# STM32H563 register map
File version: 1.6
CPU: CM33 r0p0, little endian, MPU, FPU, 4 interrupt priority bits
Registers are 32-bit, read-write, reset 0x0 unless marked. A register's access mark holds for its fields unless they carry their own. Offsets are from the block's base; [hi:lo] are bit positions; {n}, {i} and the like mark numbered series; 'fields as' and 'values as' point back to an identical list.

## GPDMA1 — General purpose direct memory access controller
Base 0x40020000
Same registers: GPDMA2 0x40021000, SEC_GPDMA1 0x50020000, SEC_GPDMA2 0x50021000
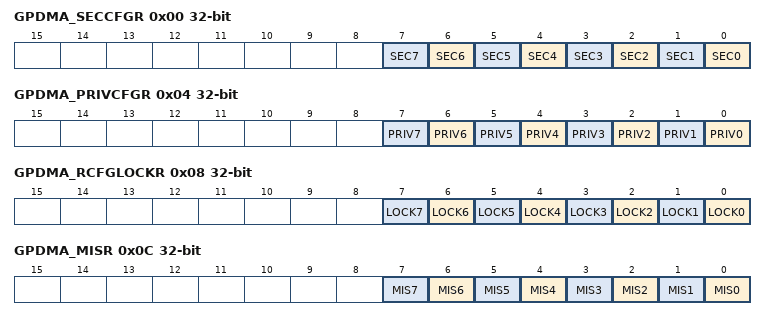
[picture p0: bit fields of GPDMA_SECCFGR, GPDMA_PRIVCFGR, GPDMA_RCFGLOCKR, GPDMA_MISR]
0x00 GPDMA_SECCFGR — GPDMA secure configuration register
  [all] fields
    0=non-secure; 1=secure
  [n] SEC{n} (n=0..7) — secure state of channel x (x = 7 to 0)
0x04 GPDMA_PRIVCFGR — GPDMA privileged configuration register
  [all] fields
    0=unprivileged; 1=privileged
  [n] PRIV{n} (n=0..7) — privileged state of channel x (x = 7 to 0)
0x08 GPDMA_RCFGLOCKR — GPDMA configuration lock register
  [all] fields
    0=secure privilege configuration of the channel x is writable; 1=secure privilege configuration of the channel x is not writable
  [n] LOCK{n} (n=0..7) — lock the configuration of GPDMA_SECCFGR.SECx and GPDMA_PRIVCFGR.PRIVx, until a global GPDMA reset (x = 7 to 0) This bit is cleared after reset and, once set, it cannot be reset until a global GPDMA reset.
0x0C GPDMA_MISR ro — GPDMA non-secure masked interrupt status register
  [all] fields
    0=no interrupt occurred on channel x; 1=an interrupt occurred on channel x
  [n] MIS{n} (n=0..7) — masked interrupt status of channel x (x = 7 to 0)
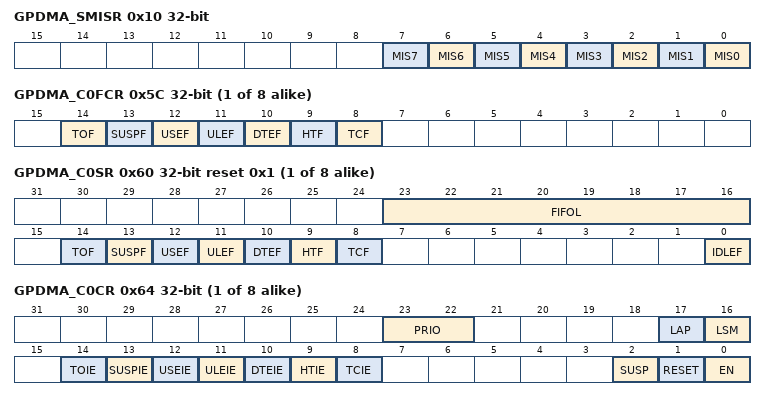
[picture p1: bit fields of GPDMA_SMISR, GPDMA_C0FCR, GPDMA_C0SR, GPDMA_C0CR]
0x10 GPDMA_SMISR ro — GPDMA secure masked interrupt status register
  [all] fields
    0=no interrupt occurred on the secure channel x; 1=an interrupt occurred on the secure channel x
  [n] MIS{n} (n=0..7) — masked interrupt status of the secure channel x (x = 7 to 0)
{0x50+0x80*i} GPDMA_C{i}LBAR (i=0..7) — GPDMA channel {i} linked-list base address register
  [31:16] LBA — linked-list base address of GPDMA channel x
{0x5C+0x80*i} GPDMA_C{i}FCR wo (i=0..7) — GPDMA channel {i} flag clear register
  [14] TOF — trigger overrun flag clear
    0=no effect; 1=corresponding TOF flag cleared
  [13] SUSPF — completed suspension flag clear
    0=no effect; 1=corresponding SUSPF flag cleared
  [12] USEF — user setting error flag clear
    0=no effect; 1=corresponding USEF flag cleared
  [11] ULEF — update link transfer error flag clear
    0=no effect; 1=corresponding ULEF flag cleared
  [10] DTEF — data transfer error flag clear
    0=no effect; 1=corresponding DTEF flag cleared
  [9] HTF — half transfer flag clear
    0=no effect; 1=corresponding HTF flag cleared
  [8] TCF — transfer complete flag clear
    0=no effect; 1=corresponding TCF flag cleared
{0x60+0x80*i} GPDMA_C{i}SR ro reset 0x1 (i=0..7) — GPDMA channel {i} status register
  [23:16] FIFOL — monitored FIFO level Number of available write beats in the FIFO, in units of the programmed destination data width (see GPDMA_CxTR1.DDW_LOG2[1:0], in units of bytes, half-words, or words). Note: After having suspended an active transfer, the user may need to read FIFOL[7:0], additionally to GPDMA_CxBR1.BDNT[15:0] and GPDMA_CxBR1.BRC[10:0], to know how many data have been transferred to the destination. Before reading, the user may wait for the transfer to be suspended (GPDMA_CxSR.SUSPF = 1).
  [14] TOF — trigger overrun flag
    0=no trigger overrun event; 1=a trigger overrun event occurred
  [13] SUSPF — completed suspension flag
    0=no completed suspension event; 1=a completed suspension event occurred
  [12] USEF — user setting error flag
    0=no user setting error event; 1=a user setting error event occurred
  [11] ULEF — update link transfer error flag
    0=no update link transfer error event; 1=a master bus error event occurred while updating a linked-list register from memory
  [10] DTEF — data transfer error flag
    0=no data transfer error event; 1=a master bus error event occurred on a data transfer
  [9] HTF — half transfer flag A half transfer event is either a half block transfer or a half 2D/repeated block transfer, depending on the transfer complete event mode (GPDMA_CxTR2.TCEM[1:0]). A half block transfer occurs when half of the bytes of the source block size (rounded up integer of GPDMA_CxBR1.BNDT[15:0]/2) has been transferred to the destination. A half 2D/repeated block transfer occurs when half of the repeated blocks (rounded up integer of (GPDMA_CxBR1.BRC[10:0]+1)/2)) has been transferred to the destination.
    0=no half transfer event; 1=a half transfer event occurred
  [8] TCF — transfer complete flag A transfer complete event is either a block transfer complete, a 2D/repeated block transfer complete, a LLI transfer complete including the upload of the next LLI if any, or the full linked-list completion, depending on the transfer complete event mode (GPDMA_CxTR2.TCEM[1:0]).
    0=no transfer complete event; 1=a transfer complete event occurred
  [0] IDLEF — idle flag This idle flag is de-asserted by hardware when the channel is enabled (GPDMA_CxCR.EN = 1) with a valid channel configuration (no USEF to be immediately reported). This idle flag is asserted after hard reset or by hardware when the channel is back in idle state (in suspended or disabled state).
    0=channel not in idle state; 1=channel in idle state
{0x64+0x80*i} GPDMA_C{i}CR access per field (i=0..7) — GPDMA channel {i} control register
  [23:22] PRIO rw — priority level of the channel x GPDMA transfer versus others Note: This bit must be written when EN = 0. This bit is read-only when EN = 1.
    0=low priority, low weight; 1=low priority, mid weight; 2=low priority, high weight; 3=high priority
  [17] LAP rw — linked-list allocated port This bit is used to allocate the master port for the update of the GPDMA linked-list registers from the memory. Note: This bit must be written when EN=0. This bit is read-only when EN=1.
    0=port 0 (AHB) allocated; 1=port 1 (AHB) allocated
  [16] LSM rw — Link step mode First the (possible 1D/repeated) block transfer is executed as defined by the current internal register file until GPDMA_CxBR1.BNDT[15:0] = 0 and GPDMA_CxBR1.BRC[10:0] = 0 if present. Secondly the next linked-list data structure is conditionally uploaded from memory as defined by GPDMA_CxLLR. Then channel execution is completed. Note: This bit must be written when EN=0. This bit is read-only when EN=1.
    0=channel executed for the full linked-list and completed at the end of the last LLI (GPDMA_CxLLR = 0). The 16 low-significant bits of the link address are null (LA[15:0] = 0) and all the update bits are null (UT1 =UB1 = UT2 = USA = UDA = ULL = 0 and UT3 = UB2 = 0 if present). Then GPDMA_CxBR1.BNDT[15:0] = 0 and GPDMA_CxBR1.BRC[10:0] = 0 if present.; 1=channel executed once for the current LLI
  [14] TOIE rw — trigger overrun interrupt enable
    0=interrupt disabled; 1=interrupt enabled
  [13] SUSPIE rw — completed suspension interrupt enable
    0=interrupt disabled; 1=interrupt enabled
  [12] USEIE rw — user setting error interrupt enable
    0=interrupt disabled; 1=interrupt enabled
  [11] ULEIE rw — update link transfer error interrupt enable
    0=interrupt disabled; 1=interrupt enabled
  [10] DTEIE rw — data transfer error interrupt enable
    0=interrupt disabled; 1=interrupt enabled
  [9] HTIE rw — half transfer complete interrupt enable
    0=interrupt disabled; 1=interrupt enabled
  [8] TCIE rw — transfer complete interrupt enable
    0=interrupt disabled; 1=interrupt enabled
  [2] SUSP rw — suspend Writing 1 into the field RESET (bit 1) causes the hardware to de-assert this bit, whatever is written into this bit 2. Else: Software must write 1 in order to suspend an active channel i.e. a channel with an ongoing GPDMA transfer over its master ports. The software must write 0 in order to resume a suspended channel, following the programming sequence detailed in .
    0=write: resume channel, read: channel not suspended; 1=write: suspend channel, read: channel suspended
  [1] RESET wo — reset This bit is write only. Writing 0 has no impact. Writing 1 implies the reset of the following: the FIFO, the channel internal state, SUSP and EN bits (whatever is written receptively in bit 2 and bit 0). The reset is effective when the channel is in steady state, meaning one of the following: - active channel in suspended state (GPDMA_CxSR.SUSPF = 1 and GPDMA_CxSR.IDLEF = GPDMA_CxCR.EN = 1) - channel in disabled state (GPDMA_CxSR.IDLEF = 1 and GPDMA_CxCR.EN = 0). After writing a RESET, to continue using this channel, the user must explicitly reconfigure the channel including the hardware-modified configuration registers (GPDMA_CxBR1, GPDMA_CxSAR and GPDMA_CxDAR) before enabling again the channel (see the programming sequence in ).
    0=no channel reset; 1=channel reset
  [0] EN rw — enable Writing 1 into the field RESET (bit 1) causes the hardware to de-assert this bit, whatever is written into this bit 0. Else: this bit is de-asserted by hardware when there is a transfer error (master bus error or user setting error) or when there is a channel transfer complete (channel ready to be configured, e.g. if LSM=1 at the end of a single execution of the LLI). Else, this bit can be asserted by software. Writing 0 into this EN bit is ignored.
    0=write: ignored, read: channel disabled; 1=write: enable channel, read: channel enabled
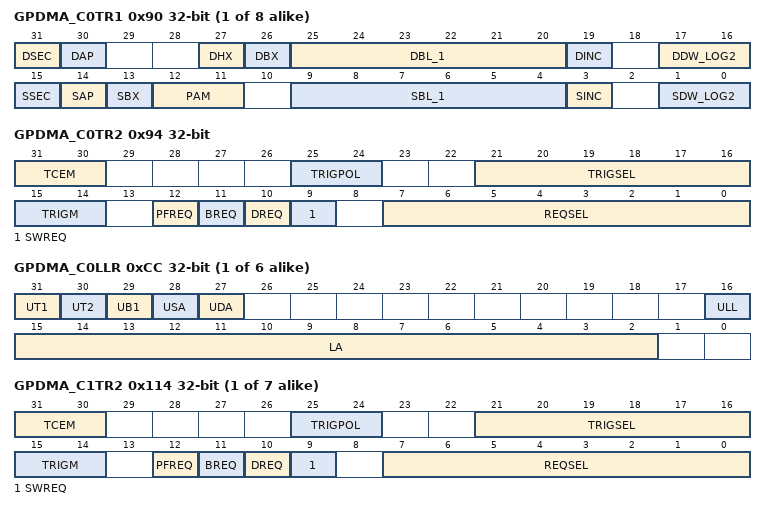
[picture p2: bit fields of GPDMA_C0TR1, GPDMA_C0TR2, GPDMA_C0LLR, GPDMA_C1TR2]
{0x90+0x80*i} GPDMA_C{i}TR1 (i=0..7) — GPDMA channel {i} transfer register 1
  [31] DSEC — security attribute of the GPDMA transfer to the destination If GPDMA_SECCFGR.SECx = 1 and the access is secure: This is a secure register bit. This bit can only be read by a secure software. This bit must be written by a secure software when GPDMA_SECCFGR.SECx = 1. A secure write is ignored when GPDMA_SECCFGR.SECx = 0. When GPDMA_SECCFGR.SECx is de-asserted, this DSEC bit is also de-asserted by hardware (on a secure reconfiguration of the channel as non-secure), and the GPDMA transfer to the destination is non-secure.
    0=GPDMA transfer non-secure; 1=GPDMA transfer secure
  [30] DAP — destination allocated port This bit is used to allocate the master port for the destination transfer Note: This bit must be written when EN = 0. This bit is read-only when EN = 1.
    0=port 0 (AHB) allocated; 1=port 1 (AHB) allocated
  [27] DHX — destination half-word exchange If the destination data size is shorter than a word, this bit is ignored. If the destination data size is a word:
    0=no halfword-based exchanged within word; 1=the two consecutive (post PAM) half-words are exchanged in each destination word
  [26] DBX — destination byte exchange If the destination data size is a byte, this bit is ignored. If the destination data size is not a byte:
    0=no byte-based exchange within half-word; 1=the two consecutive (post PAM) bytes are exchanged in each destination half-word
  [25:20] DBL_1 — destination burst length minus 1, between 0 and 63 The burst length unit is one data named beat within a burst. If DBL_1[5:0] =0 , the burst can be named as single. Each data/beat has a width defined by the destination data width DDW_LOG2[1:0]. Note: If a burst transfer crossed a 1-Kbyte address boundary on a AHB transfer, the GPDMA modifies and shortens the programmed burst into singles or bursts of lower length, to be compliant with the AHB protocol. If a burst transfer is of length greater than the FIFO size of the channel x, the GPDMA modifies and shortens the programmed burst into singles or bursts of lower length, to be compliant with the FIFO size. Transfer performance is lower, with GPDMA re-arbitration between effective and lower singles/bursts, but the data integrity is guaranteed.
  [19] DINC — destination incrementing burst The destination address, pointed by GPDMA_CxDAR, is kept constant after a burst beat/single transfer, or is incremented by the offset value corresponding to a contiguous data after a burst beat/single transfer.
    0=fixed burst; 1=contiguously incremented burst
  [17:16] DDW_LOG2 — binary logarithm of the destination data width of a burst, in bytes Note: Setting a 8-byte data width causes a user setting error to be reported and none transfer is issued. A destination burst transfer must have an aligned address with its data width (start address GPDMA_CxDAR[2:0] and address offset GPDMA_CxTR3.DAO[2:0], versus DDW_LOG2[1:0]). Otherwise a user setting error is reported and no transfer is issued.
    0=byte; 1=half-word (2 bytes); 2=word (4 bytes); 3=user setting error reported and no transfer issued
  [15] SSEC — security attribute of the GPDMA transfer from the source If GPDMA_SECCFGR.SECx = 1 and the access is secure: This is a secure register bit. This bit can only be read by a secure software. This bit must be written by a secure software when GPDMA_SECCFGR.SECx =1 . A secure write is ignored when GPDMA_SECCFGR.SECx = 0. When GPDMA_SECCFGR.SECx is de-asserted, this SSEC bit is also de-asserted by hardware (on a secure reconfiguration of the channel as non-secure), and the GPDMA transfer from the source is non-secure.
    0=GPDMA transfer non-secure; 1=GPDMA transfer secure
  [14] SAP — source allocated port This bit is used to allocate the master port for the source transfer Note: This bit must be written when EN = 0. This bit is read-only when EN = 1.
    0=port 0 (AHB) allocated; 1=port 1 (AHB) allocated
  [13] SBX — source byte exchange within the unaligned half-word of each source word If the source data width is shorter than a word, this bit is ignored. If the source data width is a word:
    0=no byte-based exchange within the unaligned half-word of each source word; 1=the two consecutive bytes within the unaligned half-word of each source word are exchanged
  [12:11] PAM — padding/alignment mode If DDW_LOG2[1:0] = SDW_LOG2[1:0]: if the data width of a burst destination transfer is equal to the data width of a burst source transfer, these bits are ignored. Else, in the following enumerated values, the condition PAM_1 is when destination data width is higher that source data width, and the condition PAM_2 is when destination data width is higher than source data width. 1x: successive source data are FIFO queued and packed at the destination data width, in a left (LSB) to right (MSB) order (named little endian), before a destination transfer 1x: source data is FIFO queued and unpacked at the destination data width, to be transferred in a left (LSB) to right (MSB) order (named little endian) to the destination Note: If the transfer from the source peripheral is configured with peripheral flow-control mode (SWREQ = 0 and PFREQ = 1 and DREQ = 0), and if the destination data width the source data width, packing is not supported.
    0=B_0x0_PAM_1 (source data is transferred as right aligned, padded with 0s up to the destination data width); 1=B_0x1_PAM_1 (source data is transferred as right aligned, sign extended up to the destination data width)
  [9:4] SBL_1 — source burst length minus 1, between 0 and 63 The burst length unit is one data named beat within a burst. If SBL_1[5:0] =0 , the burst can be named as single. Each data/beat has a width defined by the destination data width SDW_LOG2[1:0]. Note: If a burst transfer crossed a 1-Kbyte address boundary on a AHB transfer, the GPDMA modifies and shortens the programmed burst into singles or bursts of lower length, to be compliant with the AHB protocol. If a burst transfer is of length greater than the FIFO size of the channel x, the GPDMA modifies and shortens the programmed burst into singles or bursts of lower length, to be compliant with the FIFO size. Transfer performance is lower, with GPDMA re-arbitration between effective and lower singles/bursts, but the data integrity is guaranteed.
  [3] SINC — source incrementing burst The source address, pointed by GPDMA_CxSAR, is kept constant after a burst beat/single transfer or is incremented by the offset value corresponding to a contiguous data after a burst beat/single transfer.
    0=fixed burst; 1=contiguously incremented burst
  [1:0] SDW_LOG2 — binary logarithm of the source data width of a burst in bytes Note: Setting a 8-byte data width causes a user setting error to be reported and no transfer is issued. A source block size must be a multiple of the source data width (GPDMA_CxBR1.BNDT[2:0] versus SDW_LOG2[1:0]). Otherwise, a user setting error is reported and no transfer is issued. A source burst transfer must have an aligned address with its data width (start address GPDMA_CxSAR[2:0] versus SDW_LOG2[1:0]). Otherwise, a user setting error is reported and none transfer is issued.
    values as DDW_LOG2
0x94 GPDMA_C0TR2 — GPDMA channel 0 transfer register 2
  [31:30] TCEM — transfer complete event mode These bits define the transfer granularity for the transfer complete and half transfer complete events generation. Note: If the initial LLI0 data transfer is null/void (directly programmed by the internal register file with GPDMA_CxBR1.BNDT[15:0] = 0), then neither the complete transfer event nor the half transfer event is generated. Note: If the initial LLI0 data transfer is null/void (directly programmed by the internal register file with GPDMA_CxBR1.BNDT[15:0] = 0), then neither the complete transfer event nor the half transfer event is generated. Note: If the initial LLI0 data transfer is null/void (i.e. directly programmed by the internal register file with GPDMA_CxBR1.BNDT[15:0] =0 ), then the half transfer event is not generated, and the transfer complete event is generated when is completed the loading of the LLI1.
    0=at block level (when GPDMA_CxBR1.BNDT[15:0] = 0): the complete (and the half) transfer event is generated at the (respectively half of the) end of a block; 1=channel x = 0 to 11, same as 00; channel x=12 to 15, at 2D/repeated block level (when GPDMA_CxBR1.BRC[10:0] = 0 and GPDMA_CxBR1.BNDT[15:0] = 0), the complete (and the half) transfer event is generated at the end (respectively half of the end) of the 2D/repeated block; 2=at LLI level: the complete transfer event is generated at the end of the LLI transfer, including the update of the LLI if any. The half transfer event is generated at the half of the LLI data transfer (the LLI data transfer being a block transfer or a 2D/repeated block transfer for channel x = 12 to 15), if any data transfer.; 3=at channel level: the complete transfer event is generated at the end of the last LLI transfer. The half transfer event is generated at the half of the data transfer of the last LLI. The last LLI updates the link address GPDMA_CxLLR.LA[15:2] to zero and clears all the GPDMA_CxLLR update bits (UT1, UT2, UB1, USA, UDA and ULL, plus UT3 and UB2 if present). If the channel transfer is continuous/infinite, no event is generated.
  [25:24] TRIGPOL — trigger event polarity These bits define the polarity of the selected trigger event input defined by TRIGSEL[5:0].
    0=no trigger (masked trigger event); 1=trigger on the rising edge; 2=trigger on the falling edge; 3=same as 00
  [21:16] TRIGSEL — trigger event input selection These bits select the trigger event input of the GPDMA transfer (as per ), with an active trigger event if TRIGPOL[1:0] different 00.
  [15:14] TRIGM — trigger mode These bits define the transfer granularity for its conditioning by the trigger..
    0=at block level: the first burst read of each block transfer is conditioned by one hit trigger (channel x = 12 to 15, for each block if a 2D/repeated block is configured with GPDMA_CxBR1.BRC[10:0] different 0); 1=channel x = 0 to 11, same as 00; channel x=12 to 15, at 2D/repeated block level, the; 2=at link level: a LLI link transfer is conditioned by one hit trigger. The LLI data transfer (if any) is not conditioned.; 3=at programmed burst level: If SWREQ = 1, each programmed burst read is conditioned by one hit trigger. If SWREQ = 0, each programmed burst that is requested by the selected peripheral, is conditioned by one hit trigger.
  [12] PFREQ — Hardware request in peripheral flow control mode Important: If a given channel x is not implemented with this feature, this bit is reserved and PFREQ is not present (see for the list of the implemented channels with this feature. If the channel x is activated (GPDMA_CxCR.EN asserted) with SWREQ = 1 (software request for a memory-to-memory transfer), this bit is ignored. Else: Note: In peripheral flow control mode, there are the following restrictions: - no 2D/repeated block support (GPDMA_CxBR1.BRC[10:0] must be set to 0 if present) - the peripheral must be set as the source of the transfer (DREQ = 0). - data packing to a wider destination width is not supported (if destination width source data width, GPDMA_CxTR1.PAM[1] must be set to 0). - GPDMA_CxBR1.BNDT[15:0] must be programmed as a multiple of the source (peripheral) burst size.
    0=the selected hardware request is driven by a peripheral with a hardware request/acknowledge protocol in GPDMA control mode. The GPDMA is programmed with GPDMA_CxCTR1.BNDT[15:0] and this is internally used by the hardware for the block transfer completion.; 1=the selected hardware request is driven by a peripheral with a hardware request/acknowledge protocol in peripheral control mode. The GPDMA block transfer can be early completed by the peripheral itself (see for more details).
  [11] BREQ — Block hardware request If the channel x is activated (GPDMA_CxCR.EN asserted) with SWREQ = 1 (software request for a memory-to-memory transfer), this bit is ignored. Else:
    0=the selected hardware request is driven by a peripheral with a hardware request/acknowledge protocol at a burst level; 1=the selected hardware request is driven by a peripheral with a hardware request/acknowledge protocol at a block level (see )
  [10] DREQ — destination hardware request This bit is ignored if channel x is activated (GPDMA_CxCR.EN asserted) with SWREQ = 1 (software request for a memory-to-memory transfer). Else: Note: If the channel x is activated (GPDMA_CxCR.EN is asserted) with SWREQ = 0 and PFREQ = 1 (peripheral hardware request with peripheral flow-control mode), any software assertion to this DREQ bit is ignored: in peripheral flow-control mode, only a peripheral-to-memory transfer is supported.
    0=selected hardware request driven by a source peripheral (request signal taken into account by the GPDMA transfer scheduler over the source/read port); 1=selected hardware request driven by a destination peripheral (request signal taken into account by the GPDMA transfer scheduler over the destination/write port)
  [9] SWREQ — software request This bit is internally taken into account when GPDMA_CxCR.EN is asserted.
    0=no software request. The selected hardware request REQSEL[6:0] is taken into account.; 1=software request for a memory-to-memory transfer. The default selected hardware request as per REQSEL[6:0] is ignored.
  [7:0] REQSEL — GPDMA hardware request selection These bits are ignored if channel x is activated (GPDMA_CxCR.EN asserted) with SWREQ = 1 (software request for a memory-to-memory transfer). Else, the selected hardware request is internally taken into account as per . The user must not assign a same input hardware request (same REQSEL[7:0] value) to different active GPDMA channels (GPDMA_CxCR.EN = 1 and GPDMA_CxTR2.SWREQ = 0 for these channels). GPDMA is not intended to hardware support the case of simultaneous enabled channels incorrectly configured with a same hardware peripheral request signal, and there is no user setting error reporting.
{0x98+0x80*i} GPDMA_C{i}BR1 (i=0..5) — GPDMA channel {i} block register 1
  [15:0] BNDT — block number of data bytes to transfer from the source Block size transferred from the source. When the channel is enabled, this field becomes read-only and is decremented, indicating the remaining number of data items in the current source block to be transferred. BNDT[15:0] is programmed in number of bytes, maximum source block size is 64 Kbytes -1. Once the last data transfer is completed (BNDT[15:0] = 0): - if GPDMA_CxLLR.UB1 = 1, this field is updated by the LLI in the memory. - if GPDMA_CxLLR.UB1 = 0 and if there is at least one non null Uxx update bit, this field is internally restored to the programmed value. - if all GPDMA_CxLLR.Uxx = 0 and if GPDMA_CxLLR.LA[15:0] = 0, this field is internally restored to the programmed value (infinite/continuous last LLI). - if GPDMA_CxLLR = 0, this field is kept as zero following the last LLI data transfer. Note: A non-null source block size must be a multiple of the source data width (BNDT[2:0] versus GPDMA_CxTR1.SDW_LOG2[1:0]). Else a user setting error is reported and no transfer is issued. When configured in packing mode (GPDMA_CxTR1.PAM[1] = 1 and destination data width different from source data width), a non-null source block size must be a multiple of the destination data width (BNDT[2:0] versus GPDMA_CxTR1.DDW_LOG2[1:0]). Else a user setting error is reported and no transfer is issued.
{0x9C+0x80*i} GPDMA_C{i}SAR (i=0..7) — GPDMA channel {i} source address register
  [31:0] SA — source address This field is the pointer to the address from which the next data is read. During the channel activity, depending on the source addressing mode (GPDMA_CxTR1.SINC), this field is kept fixed or incremented by the data width (GPDMA_CxTR1.SDW_LOG2[1:0]) after each burst source data, reflecting the next address from which data is read. During the channel activity, this address is updated after each completed source burst, consequently to: the programmed source burst; either in fixed addressing mode or in contiguous-data incremented mode. If contiguously incremented (GPDMA_CxTR1.SINC = 1), then the additional address offset value is the programmed burst size, as defined by GPDMA_CxTR1.SBL_1[5:0] and GPDMA_CxTR1.SDW_LOG2[21:0] the additional source incremented/decremented offset value as programmed by GPDMA_CxBR1.SDEC and GPDMA_CxTR3.SAO[12:0] once/if completed source block transfer, for a channel x with 2D addressing capability (x = 12 to 15). additional block repeat source incremented/decremented offset value as programmed by GPDMA_CxBR1.BRSDEC and GPDMA_CxBR2.BRSAO[15:0] In linked-list mode, after a LLI data transfer is completed, this register is automatically updated by GPDMA from the memory, provided the LLI is set with GPDMA_CxLLR.USA = 1. Note: A source address must be aligned with the programmed data width of a source burst (SA[2:0] versus GPDMA_CxTR1.SDW_LOG2[1:0]). Else, a user setting error is reported and no transfer is issued. When the source block size is not a multiple of the source burst size and is a multiple of the source data width, the last programmed source burst is not completed and is internally shorten to match the block size. In this case, the additional GPDMA_CxTR3.SAO[12:0] is not applied.
{0xA0+0x80*i} GPDMA_C{i}DAR (i=0..7) — GPDMA channel {i} destination address register
  [31:0] DA — destination address This field is the pointer to the address from which the next data is written. During the channel activity, depending on the destination addressing mode (GPDMA_CxTR1.DINC), this field is kept fixed or incremented by the data width (GPDMA_CxTR1.DDW_LOG2[21:0]) after each burst destination data, reflecting the next address from which data is written. During the channel activity, this address is updated after each completed destination burst, consequently to: the programmed destination burst; either in fixed addressing mode or in contiguous-data incremented mode. If contiguously incremented (GPDMA_CxTR1.DINC = 1), then the additional address offset value is the programmed burst size, as defined by GPDMA_CxTR1.DBL_1[5:0] and GPDMA_CxTR1.DDW_LOG2[1:0] the additional destination incremented/decremented offset value as programmed by GPDMA_CxBR1.DDEC and GPDMA_CxTR3.DAO[12:0] once/if completed destination block transfer, for a channel x with 2D addressing capability (x = 12 to 15), the additional block repeat destination incremented/decremented offset value as programmed by GPDMA_CxBR1.BRDDEC and GPDMA_CxBR2.BRDAO[15:0] In linked-list mode, after a LLI data transfer is completed, this register is automatically updated by the GPDMA from the memory, provided the LLI is set with GPDMA_CxLLR.UDA = 1. Note: A destination address must be aligned with the programmed data width of a destination burst (DA[2:0] versus GPDMA_CxTR1.DDW_LOG2[1:0]). Else, a user setting error is reported and no transfer is issued.
{0xCC+0x80*i} GPDMA_C{i}LLR (i=0..5) — GPDMA channel {i} linked-list address register
  [31] UT1 — Update GPDMA_CxTR1 from memory This bit controls the update of GPDMA_CxTR1 from the memory during the link transfer.
    0=no GPDMA_CxTR1 update; 1=GPDMA_CxTR1 update
  [30] UT2 — Update GPDMA_CxTR2 from memory This bit controls the update of GPDMA_CxTR2 from the memory during the link transfer.
    0=no GPDMA_CxTR2 update; 1=GPDMA_CxTR2 update
  [29] UB1 — Update GPDMA_CxBR1 from memory This bit controls the update of GPDMA_CxBR1 from the memory during the link transfer. If UB1 = 0 and if GPDMA_CxLLR different 0, the linked-list is not completed. GPDMA_CxBR1.BNDT[15:0] is then restored to the programmed value after data transfer is completed and before the link transfer.
    0=no GPDMA_CxBR1 update from memory (GPDMA_CxBR1.BNDT[15:0] restored if any link transfer); 1=GPDMA_CxBR1 update
  [28] USA — update GPDMA_CxSAR from memory This bit controls the update of GPDMA_CxSAR from the memory during the link transfer.
    0=no GPDMA_CxSAR update; 1=GPDMA_CxSAR update
  [27] UDA — Update GPDMA_CxDAR register from memory This bit is used to control the update of GPDMA_CxDAR from the memory during the link transfer.
    0=no GPDMA_CxDAR update; 1=GPDMA_CxDAR update
  [16] ULL — Update GPDMA_CxLLR register from memory This bit is used to control the update of GPDMA_CxLLR from the memory during the link transfer.
    0=no GPDMA_CxLLR update; 1=GPDMA_CxLLR update
  [15:2] LA — pointer (16-bit low-significant address) to the next linked-list data structure If UT1 = UT2 = UB1 = USA = UDA = ULL = 0 and if LA[15:20] = 0, the current LLI is the last one. The channel transfer is completed without any update of the linked-list GPDMA register file. Else, this field is the pointer to the memory address offset from which the next linked-list data structure is automatically fetched from, once the data transfer is completed, in order to conditionally update the linked-list GPDMA internal register file (GPDMA_CxCTR1, GPDMA_CxTR2, GPDMA_CxBR1, GPDMA_CxSAR, GPDMA_CxDAR and GPDMA_CxLLR). Note: The user must program the pointer to be 32-bit aligned. The two low-significant bits are write ignored.
{0x94+0x80*i} GPDMA_C{i}TR2 (i=1..7) — GPDMA channel {i} transfer register 2
  [31:30] TCEM — transfer complete event mode These bits define the transfer granularity for the transfer complete and half transfer complete events generation. Note: If the initial LLI0 data transfer is null/void (directly programmed by the internal register file with GPDMA_CxBR1.BNDT[15:0] = 0), then neither the complete transfer event nor the half transfer event is generated. Note: If the initial LLI0 data transfer is null/void (directly programmed by the internal register file with GPDMA_CxBR1.BNDT[15:0] = 0), then neither the complete transfer event nor the half transfer event is generated. Note: If the initial LLI0 data transfer is null/void (i.e. directly programmed by the internal register file with GPDMA_CxBR1.BNDT[15:0] =0 ), then the half transfer event is not generated, and the transfer complete event is generated when is completed the loading of the LLI1.
    values as GPDMA_C0TR2.TCEM
  [25:24] TRIGPOL — trigger event polarity These bits define the polarity of the selected trigger event input defined by TRIGSEL[5:0].
    values as GPDMA_C0TR2.TRIGPOL
  [21:16] TRIGSEL — trigger event input selection These bits select the trigger event input of the GPDMA transfer (as per ), with an active trigger event if TRIGPOL[1:0] different 00.
  [15:14] TRIGM — trigger mode These bits define the transfer granularity for its conditioning by the trigger.
    values as GPDMA_C0TR2.TRIGM
  [12] PFREQ — Hardware request in peripheral flow control mode Important: If a given channel x is not implemented with this feature, this bit is reserved and PFREQ is not present (see for the list of the implemented channels with this feature. If the channel x is activated (GPDMA_CxCR.EN asserted) with SWREQ = 1 (software request for a memory-to-memory transfer), this bit is ignored. Else: Note: In peripheral flow control mode, there are the following restrictions: - no 2D/repeated block support (GPDMA_CxBR1.BRC[10:0] must be set to 0 if present) - the peripheral must be set as the source of the transfer (DREQ = 0). - data packing to a wider destination width is not supported (if destination width source data width, GPDMA_CxTR1.PAM[1] must be set to 0). - GPDMA_CxBR1.BNDT[15:0] must be programmed as a multiple of the source (peripheral) burst size.
    values as GPDMA_C0TR2.PFREQ
  [11] BREQ — Block hardware request If the channel x is activated (GPDMA_CxCR.EN asserted) with SWREQ = 1 (software request for a memory-to-memory transfer), this bit is ignored. Else:
    values as GPDMA_C0TR2.BREQ
  [10] DREQ — destination hardware request This bit is ignored if channel x is activated (GPDMA_CxCR.EN asserted) with SWREQ = 1 (software request for a memory-to-memory transfer). Else: Note: If the channel x is activated (GPDMA_CxCR.EN is asserted) with SWREQ = 0 and PFREQ = 1 (peripheral hardware request with peripheral flow-control mode), any software assertion to this DREQ bit is ignored: in peripheral flow-control mode, only a peripheral-to-memory transfer is supported.
    values as GPDMA_C0TR2.DREQ
  [9] SWREQ — software request This bit is internally taken into account when GPDMA_CxCR.EN is asserted.
    values as GPDMA_C0TR2.SWREQ
  [7:0] REQSEL — GPDMA hardware request selection These bits are ignored if channel x is activated (GPDMA_CxCR.EN asserted) with SWREQ = 1 (software request for a memory-to-memory transfer). Else, the selected hardware request is internally taken into account as per . The user must not assign a same input hardware request (same REQSEL[7:0] value) to different active GPDMA channels (GPDMA_CxCR.EN = 1 and GPDMA_CxTR2.SWREQ = 0 for these channels). GPDMA is not intended to hardware support the case of simultaneous enabled channels incorrectly configured with a same hardware peripheral request signal, and there is no user setting error reporting.
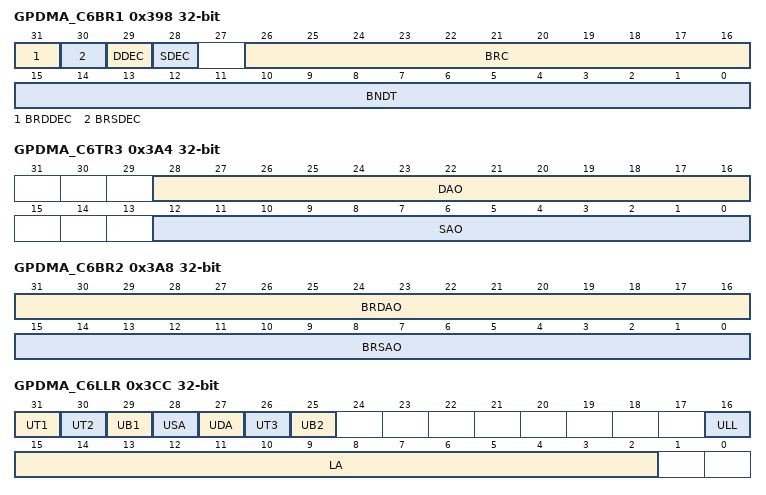
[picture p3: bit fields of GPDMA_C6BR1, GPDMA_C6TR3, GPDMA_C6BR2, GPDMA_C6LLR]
0x398 GPDMA_C6BR1 — GPDMA channel 6 alternate block register 1
  [31] BRDDEC — Block repeat destination address decrement Note: On top of this increment/decrement (depending on BRDDEC), GPDMA_CxDAR is in the same time also updated by the increment/decrement (depending on DDEC) of the GPDMA_CxTR3.DAO value, as it is usually done at the end of each programmed burst transfer.
    0=at the end of a block transfer, the GPDMA_CxDAR register is updated by adding the programmed offset GPDMA_CxBR2.BRDAO to the current GPDMA_CxDAR value (current destination address); 1=at the end of a block transfer, the GPDMA_CxDAR register is updated by subtracting the programmed offset GPDMA_CxBR2.BRDAO from the current GPDMA_CxDAR value (current destination address)
  [30] BRSDEC — Block repeat source address decrement Note: On top of this increment/decrement (depending on BRSDEC), GPDMA_CxSAR is in the same time also updated by the increment/decrement (depending on SDEC) of the GPDMA_CxTR3.SAO value, as it is done after any programmed burst transfer.
    0=at the end of a block transfer, the GPDMA_CxSAR register is updated by adding the programmed offset GPDMA_CxBR2.BRSAO to the current GPDMA_CxSAR value (current source address); 1=at the end of a block transfer, the GPDMA_CxSAR register is updated by subtracting the programmed offset GPDMA_CxBR2.BRSAO from the current GPDMA_CxSAR value (current source address)
  [29] DDEC — destination address decrement
    0=At the end of a programmed burst transfer to the destination, the GPDMA_CxDAR register is updated by adding the programmed offset GPDMA_CxTR3.DAO to the current GPDMA_CxDAR value (current destination address); 1=At the end of a programmed burst transfer to the destination, the GPDMA_CxDAR register is updated by subtracting the programmed offset GPDMA_CxTR3.DAO to the current GPDMA_CxDAR value (current destination address)
  [28] SDEC — source address decrement
    0=At the end of a programmed burst transfer from the source, the GPDMA_CxSAR register is updated by adding the programmed offset GPDMA_CxTR3.SAO to the current GPDMA_CxSAR value (current source address); 1=At the end of a programmed burst transfer from the source, the GPDMA_CxSAR register is updated by subtracting the programmed offset GPDMA_CxTR3.SAO to the current GPDMA_CxSAR value (current source address)
  [26:16] BRC — Block repeat counter This field contains the number of repetitions of the current block (0 to 2047). When the channel is enabled, this field becomes read-only. After decrements, this field indicates the remaining number of blocks, excluding the current one. This counter is hardware decremented for each completed block transfer. Once the last block transfer is completed (BRC[10:0] = BNDT[15:0] = 0): If GPDMA_CxLLR.UB1 = 1, all GPDMA_CxBR1 fields are updated by the next LLI in the memory. If GPDMA_CxLLR.UB1 = 0 and if there is at least one not null Uxx update bit, this field is internally restored to the programmed value. if all GPDMA_CxLLR.Uxx = 0 and if GPDMA_CxLLR.LA[15:0] different 0, this field is internally restored to the programmed value (infinite/continuous last LLI). if GPDMA_CxLLR = 0, this field is kept as zero following the last LLI and data transfer.
  [15:0] BNDT — block number of data bytes to transfer from the source Block size transferred from the source. When the channel is enabled, this field becomes read-only and is decremented, indicating the remaining number of data items in the current source block to be transferred. BNDT[15:0] is programmed in number of bytes, maximum source block size is 64 Kbytes -1. Once the last data transfer is completed (BNDT[15:0] = 0): - if GPDMA_CxLLR.UB1 = 1, this field is updated by the LLI in the memory. - if GPDMA_CxLLR.UB1 = 0 and if there is at least one not null Uxx update bit, this field is internally restored to the programmed value. - if all GPDMA_CxLLR.Uxx = 0 and if GPDMA_CxLLR.LA[15:0] different 0, this field is internally restored to the programmed value (infinite/continuous last LLI). - if GPDMA_CxLLR = 0, this field is kept as zero following the last LLI data transfer. Note: A non-null source block size must be a multiple of the source data width (BNDT[2:0] versus GPDMA_CxTR1.SDW_LOG2[1:0]). Else a user setting error is reported and no transfer is issued. When configured in packing mode (GPDMA_CxTR1.PAM[1]=1 and destination data width different from source data width), a non-null source block size must be a multiple of the destination data width (BNDT[2:0] versus GPDMA_CxTR1.DDW_LOG2[1:0]). Else a user setting error is reported and no transfer is issued.
0x3A4 GPDMA_C6TR3 — GPDMA channel 6 transfer register 3
  [28:16] DAO — destination address offset increment The destination address, pointed by GPDMA_CxDAR, is incremented or decremented (depending on GPDMA_CxBR1.DDEC) by this offset DAO[12:0] for each programmed destination burst. This offset is not including and is added to the programmed burst size when the completed burst is addressed in incremented mode (GPDMA_CxTR1.DINC = 1). Note: A destination address offset must be aligned with the programmed data width of a destination burst (DAO[2:0] versus GPDMA_CxTR1.DDW_LOG2[1:0]). Else, a user setting error is reported and no transfer is issued.
  [12:0] SAO — source address offset increment The source address, pointed by GPDMA_CxSAR, is incremented or decremented (depending on GPDMA_CxBR1.SDEC) by this offset SAO[12:0] for each programmed source burst. This offset is not including and is added to the programmed burst size when the completed burst is addressed in incremented mode (GPDMA_CxTR1.SINC = 1). Note: A source address offset must be aligned with the programmed data width of a source burst (SAO[2:0] versus GPDMA_CxTR1.SDW_LOG2[1:0]). Else a user setting error is reported and none transfer is issued. When the source block size is not a multiple of the destination burst size and is a multiple of the source data width, then the last programmed source burst is not completed and is internally shorten to match the block size. In this case, the additional GPDMA_CxTR3.SAO[12:0] is not applied.
0x3A8 GPDMA_C6BR2 — GPDMA channel 6 block register 2
  [31:16] BRDAO — Block repeated destination address offset For a channel with 2D addressing capability, this field is used to update (by addition or subtraction depending on GPDMA_CxBR1.BRDDEC) the current destination address (GPDMA_CxDAR) at the end of a block transfer. Note: A block repeated destination address offset must be aligned with the programmed data width of a destination burst (BRDAO[2:0] versus GPDMA_CxTR1.DDW_LOG2[1:0]). Else a user setting error is reported and no transfer is issued. BRDAO[15:0] must be set to 0 in peripheral flow-control mode (if GPDMA_CxTR2.PFREQ = 1).
  [15:0] BRSAO — Block repeated source address offset For a channel with 2D addressing capability, this field is used to update (by addition or subtraction depending on GPDMA_CxBR1.BRSDEC) the current source address (GPDMA_CxSAR) at the end of a block transfer. Note: A block repeated source address offset must be aligned with the programmed data width of a source burst (BRSAO[2:0] versus GPDMA_CxTR1.SDW_LOG2[1:0]). Else a user setting error is reported and no transfer is issued. BRSAO[15:0] must be set to 0 in peripheral flow-control mode (if GPDMA_CxTR2.PFREQ = 1).
0x3CC GPDMA_C6LLR — GPDMA channel 6 alternate linked-list address register
  [31] UT1 — Update GPDMA_CxTR1 from memory This bit controls the update of GPDMA_CxTR1 from the memory during the link transfer.
    0=no GPDMA_CxTR1 update; 1=GPDMA_CxTR1 update
  [30] UT2 — Update GPDMA_CxTR2 from memory This bit controls the update of GPDMA_CxTR2 from the memory during the link transfer.
    0=no GPDMA_CxTR2 update; 1=GPDMA_CxTR2 update
  [29] UB1 — Update GPDMA_CxBR1 from memory This bit controls the update of GPDMA_CxBR1 from the memory during the link transfer. If UB1 = 0 and if GPDMA_CxLLR different 0, the linked-list is not completed. GPDMA_CxBR1.BNDT[15:0] is then restored to the programmed value after data transfer is completed and before the link transfer.
    values as GPDMA_C0LLR.UB1
  [28] USA — update GPDMA_CxSAR from memory This bit controls the update of GPDMA_CxSAR from the memory during the link transfer.
    0=no GPDMA_CxSAR update; 1=GPDMA_CxSAR update
  [27] UDA — Update GPDMA_CxDAR register from memory This bit is used to control the update of GPDMA_CxDAR from the memory during the link transfer.
    0=no GPDMA_CxDAR update; 1=GPDMA_CxDAR update
  [26] UT3 — Update GPDMA_CxTR3 from memory This bit controls the update of GPDMA_CxTR3 from the memory during the link transfer.
    0=no GPDMA_CxTR3 update; 1=GPDMA_CxTR3 update
  [25] UB2 — Update GPDMA_CxBR2 from memory This bit controls the update of GPDMA_CxBR2 from the memory during the link transfer.
    0=no GPDMA_CxBR2 update; 1=GPDMA_CxBR2 update
  [16] ULL — Update GPDMA_CxLLR register from memory This bit is used to control the update of GPDMA_CxLLR from the memory during the link transfer.
    0=no GPDMA_CxLLR update; 1=GPDMA_CxLLR update
  [15:2] LA — pointer (16-bit low-significant address) to the next linked-list data structure If UT1 = UT2 = UB1 = USA = UDA = ULL = 0 and if LA[15:20] = 0, the current LLI is the last one. The channel transfer is completed without any update of the linked-list GPDMA register file. Else, this field is the pointer to the memory address offset from which the next linked-list data structure is automatically fetched from, once the data transfer is completed, in order to conditionally update the linked-list GPDMA internal register file (GPDMA_CxCTR1, GPDMA_CxTR2, GPDMA_CxBR1, GPDMA_CxSAR, GPDMA_CxDAR and GPDMA_CxLLR). Note: The user must program the pointer to be 32-bit aligned. The two low-significant bits are write ignored.
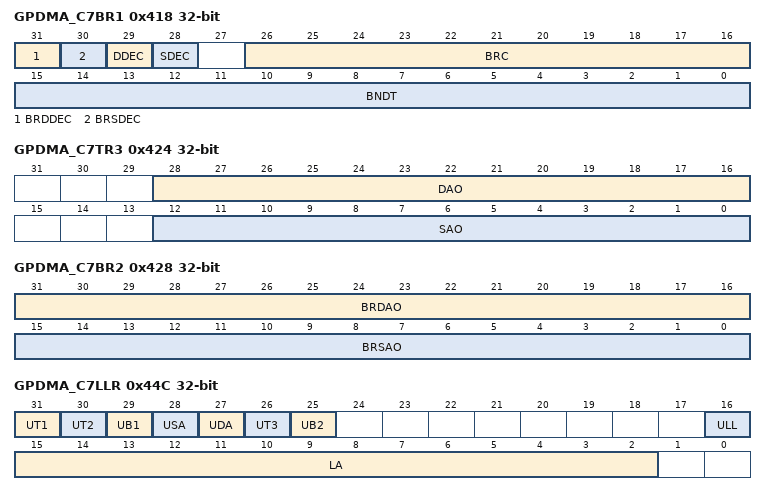
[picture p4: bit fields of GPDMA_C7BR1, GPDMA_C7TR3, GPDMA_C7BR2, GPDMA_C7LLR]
0x418 GPDMA_C7BR1 — GPDMA channel 7 alternate block register 1
  fields as GPDMA_C6BR1
0x424 GPDMA_C7TR3 — GPDMA channel 7 transfer register 3
  fields as GPDMA_C6TR3
0x428 GPDMA_C7BR2 — GPDMA channel 7 block register 2
  fields as GPDMA_C6BR2
0x44C GPDMA_C7LLR — GPDMA channel 7 alternate linked-list address register
  fields as GPDMA_C6LLR
